VERSION "HL-Global-Mobility-Team2 CAN FD protocol v5, 64-byte bidirectional payloads"

NS_ :

BS_:

BU_: IndustrialPC dSPACE

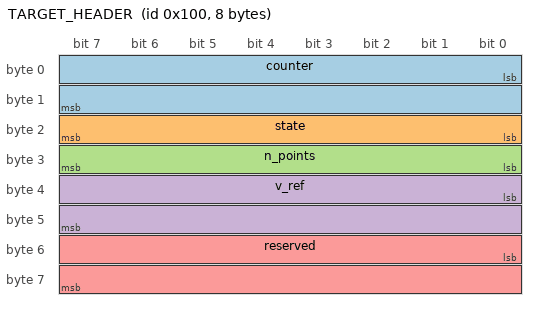
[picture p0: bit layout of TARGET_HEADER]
BO_ 256 TARGET_HEADER: 8 IndustrialPC
 SG_ counter : 0|16@1+ (1,0) [0|65535] "" dSPACE
 SG_ state : 16|8@1+ (1,0) [0|5] "" dSPACE
 SG_ n_points : 24|8@1+ (1,0) [0|255] "" dSPACE
 SG_ v_ref : 32|16@1- (0.001,0) [-32.767|32.767] "m/s" dSPACE
 SG_ reserved : 48|16@1+ (1,0) [0|65535] "" dSPACE

BO_ 257 MPC_TARGET_FD: 64 IndustrialPC
 SG_ x : 0|64@1- (1,0) [-100000|100000] "m" dSPACE
 SG_ y : 64|64@1- (1,0) [-100000|100000] "m" dSPACE
 SG_ yaw : 128|64@1- (1,0) [-100000|100000] "rad" dSPACE
 SG_ curvature : 192|64@1- (1,0) [-1000|1000] "1/m" dSPACE
 SG_ dx : 256|64@1- (1,0) [-100000|100000] "" dSPACE
 SG_ dy : 320|64@1- (1,0) [-100000|100000] "" dSPACE
 SG_ dyaw : 384|64@1- (1,0) [-100000|100000] "" dSPACE
 SG_ update : 448|64@1+ (1,0) [0|18446744073709551615] "" dSPACE

BO_ 512 VEH_FEEDBACK_FD: 64 dSPACE
 SG_ x : 0|64@1- (1,0) [-100000|100000] "m" IndustrialPC
 SG_ y : 64|64@1- (1,0) [-100000|100000] "m" IndustrialPC
 SG_ yaw : 128|64@1- (1,0) [-100000|100000] "rad" IndustrialPC
 SG_ v : 192|64@1- (1,0) [-1000|1000] "m/s" IndustrialPC
 SG_ str : 256|64@1- (1,0) [-100|100] "rad" IndustrialPC
 SG_ str_ref : 320|64@1- (1,0) [-100|100] "rad" IndustrialPC
 SG_ counter : 384|64@1+ (1,0) [0|18446744073709551615] "" IndustrialPC
 SG_ reserved : 448|64@1+ (1,0) [0|18446744073709551615] "" IndustrialPC

CM_ "CAN FD protocol using standard 11-bit identifiers with bit-rate switching enabled. Configure nominal and data bit rates identically on IndustrialPC and dSPACE.";
CM_ BO_ 256 "PC-to-dSPACE header at CAN ID 0x100. Integer fields retain the prior layout; v_ref remains signed 16-bit fixed-point with 0.001 m/s resolution.";
CM_ BO_ 257 "PC-to-dSPACE frame at CAN ID 0x101. Payload bytes 0 through 55 contain seven IEEE-754 float64 values; bytes 56 through 63 contain uint64 update.";
CM_ BO_ 512 "dSPACE-to-PC frame at CAN ID 0x200. Payload bytes 0 through 47 contain six IEEE-754 float64 values; bytes 48 through 63 contain uint64 counter and uint64 reserved.";
CM_ SG_ 257 dyaw "Clockwise-positive yaw delta [rad], negated once from internal CCW-positive localization delta at CAN TX. dx remains forward-positive and dy left-positive.";
CM_ SG_ 257 update "Unsigned 64-bit localization sample sequence in payload bytes 56 through 63, little-endian. Valid in LANE(0)/WAYPOINT(1)/PARKING(3)/TRAFFIC(4); AVOID sends zero. In valid states, consumer applies dx/dy/dyaw once only when update differs from last_update; reset last_update on state changes.";
CM_ SG_ 512 counter "Unsigned 64-bit validation counter in payload bytes 48 through 55, little-endian.";
CM_ SG_ 512 reserved "Unsigned 64-bit reserved validation field in payload bytes 56 through 63, little-endian. Transmitter should set zero unless otherwise defined.";

BA_DEF_ "BusType" STRING ;
BA_DEF_ BO_ "VFrameFormat" ENUM "StandardCAN","ExtendedCAN","reserved","J1939PG","reserved","reserved","reserved","reserved","reserved","reserved","reserved","reserved","reserved","reserved","StandardCAN_FD","ExtendedCAN_FD";
BA_DEF_ BO_ "CANFD_BRS" ENUM "0","1";
BA_DEF_ BO_ "GenMsgCycleTime" INT 0 65535;
BA_DEF_DEF_ "BusType" "CAN";
BA_DEF_DEF_ "VFrameFormat" "StandardCAN";
BA_DEF_DEF_ "CANFD_BRS" "1";
BA_DEF_DEF_ "GenMsgCycleTime" 0;
BA_ "BusType" "CAN FD";

BA_ "VFrameFormat" BO_ 256 14;
BA_ "GenMsgCycleTime" BO_ 256 10;
BA_ "VFrameFormat" BO_ 257 14;
BA_ "GenMsgCycleTime" BO_ 257 10;
BA_ "VFrameFormat" BO_ 512 14;
BA_ "GenMsgCycleTime" BO_ 512 10;

VAL_ 256 state 0 "lane" 1 "waypoint" 2 "avoid" 3 "parking" 4 "traffic" 5 "estop";

SIG_VALTYPE_ 257 x : 2;
SIG_VALTYPE_ 257 y : 2;
SIG_VALTYPE_ 257 yaw : 2;
SIG_VALTYPE_ 257 curvature : 2;
SIG_VALTYPE_ 257 dx : 2;
SIG_VALTYPE_ 257 dy : 2;
SIG_VALTYPE_ 257 dyaw : 2;
SIG_VALTYPE_ 512 x : 2;
SIG_VALTYPE_ 512 y : 2;
SIG_VALTYPE_ 512 yaw : 2;
SIG_VALTYPE_ 512 v : 2;
SIG_VALTYPE_ 512 str : 2;
SIG_VALTYPE_ 512 str_ref : 2;
